# T113-S3 register map
Vendor: Allwinner; Series: T113-S3; File version: 0.1
CPU: other 0, little endian, MPU, no FPU, 0 interrupt priority bits
Registers are 32-bit, read-write, reset 0x0 unless marked. A register's access mark holds for its fields unless they carry their own. Offsets are from the block's base; [hi:lo] are bit positions; {n}, {i} and the like mark numbered series.

## Spinlock
Base 0x03005000
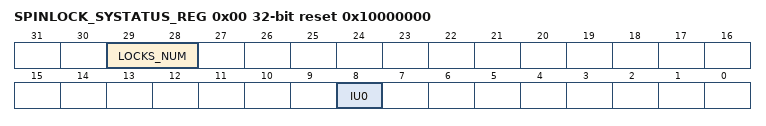
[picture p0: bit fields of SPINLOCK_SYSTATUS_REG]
0x00 SPINLOCK_SYSTATUS_REG reset 0x10000000 — Spinlock System Status Register
  [29:28] LOCKS_NUM ro — Number of lock registers implemented 00: This instance has 256 lock registers 01: This instance has 32 lock registers 10: This instance has 64 lock registers 11: This instance has 128 lock registers
    0=This instance has 256 lock registers; 1=This instance has 32 lock registers; 2=This instance has 64 lock registers; 3=This instance has 128 lock registers
  [8] IU0 ro — In-Use flag0, covering lock register0-31 0: All lock registers 0-31 are in the NotTaken state. 1: At least one of the lock register 0-31 is in the Taken state.
    0=All (All lock registers 0-31 are in the NotTaken state.); 1=At (At least one of the lock register 0-31 is in the Taken state.)
0x10 SPINLOCK_STATUS_REG — Spinlock Status Register
  [31:0] LOCK_REG_STATUS ro — SpinLock[i] status 0: The Spinlock is free 1: The Spinlock is taken
0x20 SPINLOCK_IRQ_EN_REG — Spinlock Interrupt Enable Register
  [31:0] LOCK_IRQ_EN — SpinLock[i] interrupt enable 0: Disable 1: Enable
0x40 SPINLOCK_IRQ_STA_REG — Spinlock Interrupt Status Register
  [31:0] LOCK_IRQ_STATUS write-1-clears — SpinLock[i] interrupt status 0: No effect 1: Pending Writing 1 clears this bit.
{0x80+4i} SPINLOCK_LOCKIN{i}_REG reset 0x77777777 (i=0..4)
  [31:0] LOCKID{i} ro
{0x100+4i} SPINLOCKN_LOCK_REG[{i}] (i=0..31) — SPINLOCKN_LOCK_REG[{i}]
  [0] TAKEN — Lock State Read 0x0: The lock was previously Not Taken (free). The requester is granted the lock. Write 0x0: Set the lock to Not Taken (free). Read 0x1: The lock was previously Taken. The requester is not granted the lock and must retry. Write 0x1: No update to the lock value.

## THS
Base 0x02009400
0x00 THS_CTRL reset 0x1DF002F — THS Control Register
  [31:16] TACQ — ADC acquire time CLK_IN/(n + 1) The default value is 2 us.
0x04 THS_EN — THS Enable Register
  [0] THS_EN — Enable temperature measurement sensor 0: Disable 1: Enable
    0=Disable; 1=Enable
0x08 THS_PER reset 0x3A000 — THS Period Control Register
  [31:12] THERMAL_PER — Temperature measurement period 4096*(n + 1)/CLK_IN The default value is 10 ms.
0x10 THS_DATA_INTC — THS Data Interrupt Control Register
  [0] THS_DATA_IRQ_EN — Enable the interrupt of sensor_data update If enabled, when the measured sensor_data is updated, it will generate an interrupt. 0: Disabled 1: Enabled
    0=Disabled; 1=Enabled
0x14 THS_SHUT_INTC — THS Shut Interrupt Control Register
  [0] SHUT_INT_EN — Enable the shutdown interrupt for the sensor 0: Disabled 1: Enabled
    0=Disabled; 1=Enabled
0x18 THS_ALARM_INTC — THS Alarm Interrupt Control Register
  [0] ALARM_INT_EN — Enable the alarm interrupt for the sensor 0: Disabled 1: Enabled
    0=Disabled; 1=Enabled
0x20 THS_DATA_INTS — THS Data Interrupt Status Register
  [0] THS_DATA_IRQ_STS write-1-clears — Indicates the pending status of the sensor`s data interrupt. Write 1 to clear the pending status. 0: No effect 1: Pending
    0=No_effect; 1=Pending
0x24 THS_SHUT_INTS — THS Shut Interrupt Status Register
  [0] SHUT_INT_STS write-1-clears — Indicates the pending status of the sensor`s shutdown interrupt. Write 1 to clear the pending status. 0: No effect 1: Pending
    0=No_effect; 1=Pending
0x28 THS_ALARM0_INTS
  [0] ALARM_OFF_STS write-1-clears — Alarm interrupt off pending for sensor Write 1 to clear the pending status. 0: No effect 1: Pending
    0=No_effect; 1=Pending
0x2C THS_ALARM_INTS — THS Alarm Interrupt Status Register
  [0] ALARM_INT_STS write-1-clears — Alarm interrupt pending for sensor Write 1 to clear the pending status. 0: No effect 1: Pending
    0=No_effect; 1=Pending
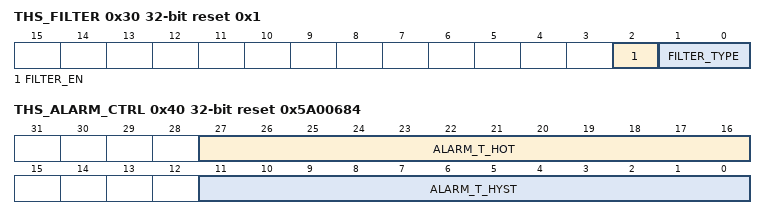
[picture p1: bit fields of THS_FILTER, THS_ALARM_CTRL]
0x30 THS_FILTER reset 0x1 — THS Median Filter Control Register
  [2] FILTER_EN — Filter enable 0: Disabled 1: Enabled
    0=Disabled; 1=Enabled
  [1:0] FILTER_TYPE — Averaging filter type 00: 2 01: 4 10: 8 11: 16
    0=_2; 1=_4; 2=_8; 3=_16
0x40 THS_ALARM_CTRL reset 0x5A00684 — THS Alarm Threshold Control Register
  [27:16] ALARM_T_HOT — Thermal sensor alarm threshold for hot temperature
  [11:0] ALARM_T_HYST — Thermal sensor alarm threshold for hysteresis temperature
0x80 THS_SHUTDOWN_CTRL reset 0x4E9 — THS Shutdown Threshold Control Register
  [11:0] SHUT_T_HOT — Thermal sensor shutdown threshold for hot temperature
0xA0 THS_CDATA reset 0x800 — THS Calibration Data
  [11:0] THS_CDATA — Thermal sensor calibration data
0xC0 THS_DATA
  [11:0] THS_DATA ro — Temperature measurement data of sensor

## TVE_TOP
Base 0x05600000
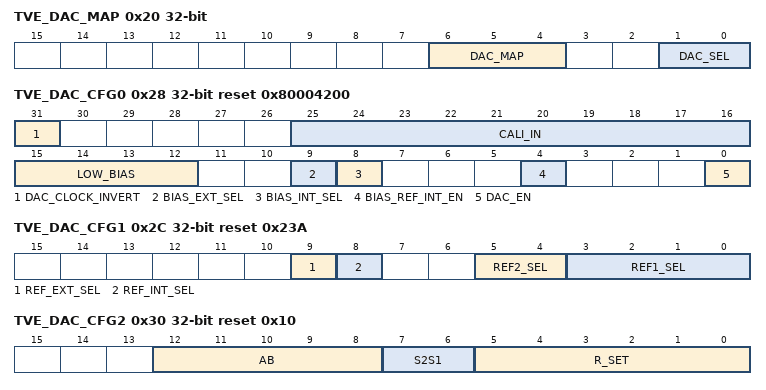
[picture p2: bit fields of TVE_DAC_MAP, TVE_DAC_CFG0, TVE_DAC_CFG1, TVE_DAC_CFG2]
0x20 TVE_DAC_MAP — TV Encoder DAC MAP Register
  [6:4] DAC_MAP — 000: OUT0 Others: Reserved
    0=OUT0 (OUT0 Others: Reserved)
  [1:0] DAC_SEL — 00: Reserved 01: TVE0 10: Reserved 11: Reserved
    1=TVE0
0x24 TVE_DAC_STATUS — TV Encoder DAC STAUTS Register
  [1:0] DAC_STATUS ro — 00: Unconnected 01: Connected 11: Short to ground 10: Reserved
    0=Unconnected; 1=Connected; 3=Short to ground
0x28 TVE_DAC_CFG0 reset 0x80004200 — TV Encoder DAC CFG0 Register
  [31] DAC_CLOCK_INVERT — 0: Not invert 1: Invert
    0=Not_invert; 1=Invert
  [25:16] CALI_IN
  [15:12] LOW_BIAS — 500 uA to 4 mA
  [9] BIAS_EXT_SEL — 0: Disable 1: Enable (A_SEL_BIAS_ADDA)
    0=Disable; 1=Enable (A_SEL_BIAS_ADDA)
  [8] BIAS_INT_SEL — 0: Disable 1: Enable (A_SEL_BIAS_RES)
    0=Disable; 1=Enable (A_SEL_BIAS_RES)
  [4] BIAS_REF_INT_EN — 0: Disable 1: Enable (A_EN_RESREF)
    0=Disable; 1=Enable (A_EN_RESREF)
  [0] DAC_EN — 0: Disable 1: Enable
    0=Disable; 1=Enable
0x2C TVE_DAC_CFG1 reset 0x23A — TV Encoder DAC CFG1 Register
  [9] REF_EXT_SEL — 0: Disable 1: Enable (A_SEL_DETREF_LDO)
    0=Disable; 1=Enable (A_SEL_DETREF_LDO)
  [8] REF_INT_SEL — 0: Disable 1: Enable (A_SEL_DETREF_RES)
    0=Disable; 1=Enable (A_SEL_DETREF_RES)
  [5:4] REF2_SEL — 00: 0.25 V 01: 0.30 V 10: 0.35 V 11: 0.40 V (a_refslct2<1:0>)
    0=_0_point_25_V (0.25 V); 1=_0_point_30_V (0.30 V); 2=_0_point_35_V (0.35 V); 3=_0_point_40_V (0.40 V (a_refslct2<1:0>))
  [3:0] REF1_SEL — 0000: 0.50 V 0001: 0.55 V 0010: 0.60 V 0011: 0.65 V 0100: 0.70 V 0101: 0.75 V 0110: 0.80 V 0111: 0.85 V 1000: 0.90 V 1001: 0.95 V 1010: 1.00 V 1011: 1.05 V 1100: 1.10 V 1101: 1.15 V 1110: 1.20 V 1111: 1.25 V (a_refslct1<3:0>) The reference voltage is used for hot plug detect function.
    0=_0_point_50_V (0.50 V); 1=_0_point_55_V (0.55 V); 2=_0_point_60_V (0.60 V); 3=_0_point_65_V (0.65 V); 4=_0_point_70_V (0.70 V); 5=_0_point_75_V (0.75 V); 6=_0_point_80_V (0.80 V); 7=_0_point_85_V (0.85 V); 8=_0_point_90_V (0.90 V); 9=_0_point_95_V (0.95 V); 10=_1_point_00_V (1.00 V); 11=_1_point_05_V (1.05 V); 12=_1_point_10_V (1.10 V); 13=_1_point_15_V (1.15 V); 14=_1_point_20_V (1.20 V); 15=_1_point_25_V (1.25 V (a_refslct1<3:0>) The reference voltage is used for hot plug detect function.)
0x30 TVE_DAC_CFG2 reset 0x10 — TV Encoder DAC CFG2 Register
  [12:8] AB — ( I config output current for different peak voltage)
  [7:6] S2S1
  [5:0] R_SET
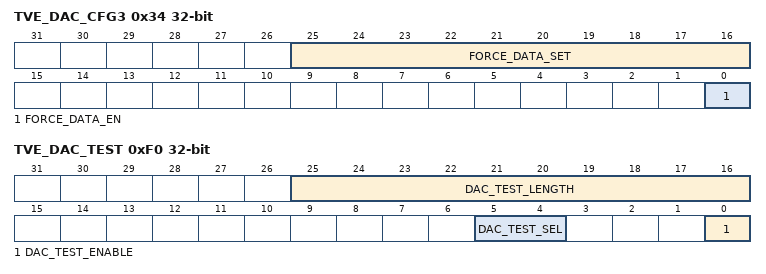
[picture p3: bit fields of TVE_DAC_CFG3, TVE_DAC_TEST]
0x34 TVE_DAC_CFG3 — TV Encoder DAC CFG2 Register
  [25:16] FORCE_DATA_SET — Force DAC input data
  [0] FORCE_DATA_EN — 0: DAC input data from TVE 1: DAC input data from FORCE_DATA_SET
    0=DAC_input_data_from_TVE; 1=DAC_input_data_from_FORCE_DATA_SET
0xF0 TVE_DAC_TEST — TV Encoder DAC TEST Register
  [25:16] DAC_TEST_LENGTH — DAC TEST DATA LENGTH
  [5:4] DAC_TEST_SEL — 00: DAC0 Others: Reserved
    0=DAC0 (DAC0 Others: Reserved)
  [0] DAC_TEST_ENABLE — 0: Reserved 1: Repeat DAC data from DAC sram
    1=Repeat DAC data from DAC sram
